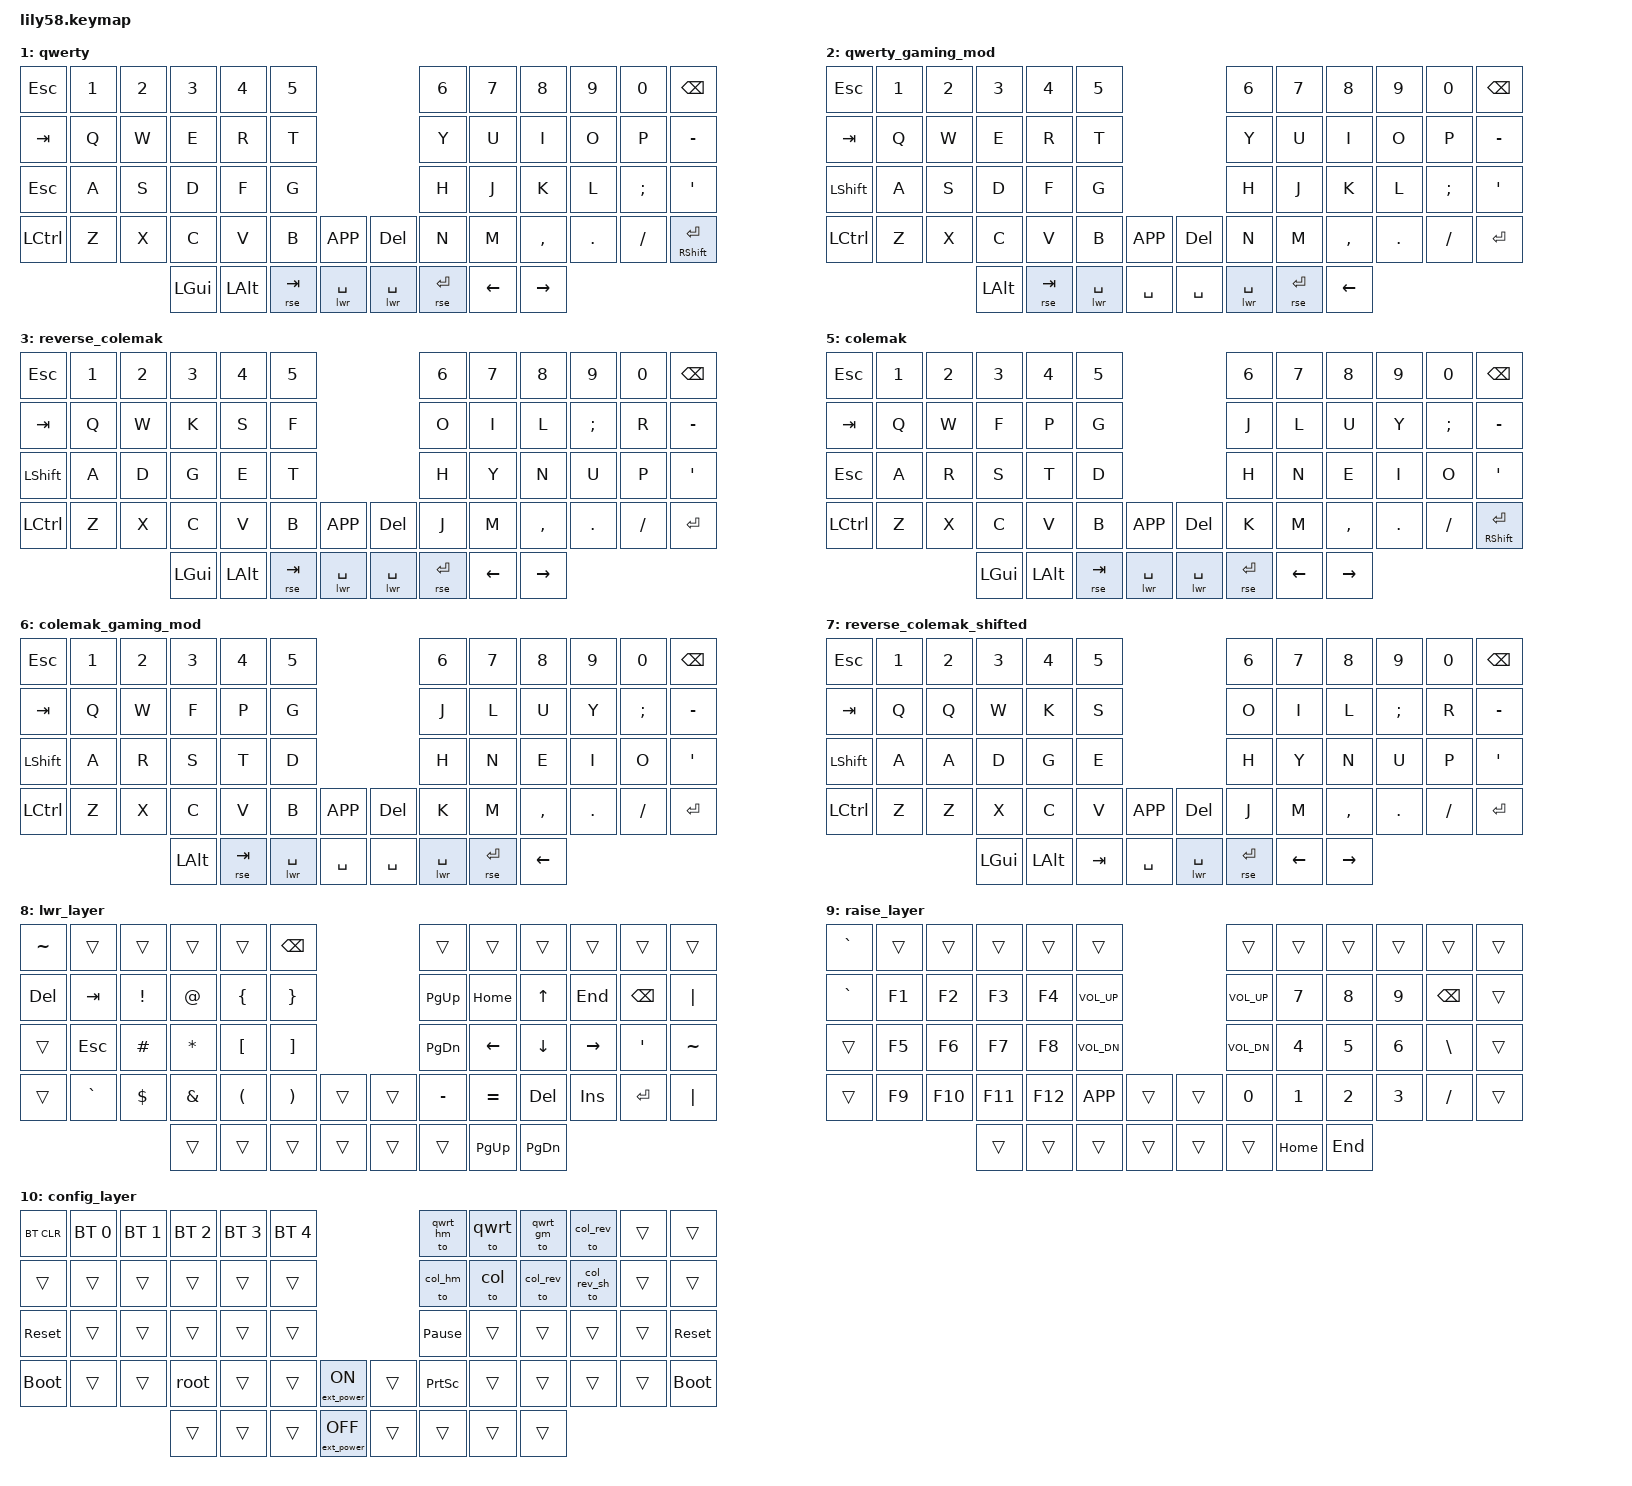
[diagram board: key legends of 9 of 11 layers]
/*
 * Copyright (c) 2020 The ZMK Contributors
 *
 * SPDX-License-Identifier: MIT
 */

#include <behaviors.dtsi>
#include <dt-bindings/zmk/bt.h>
#include <dt-bindings/zmk/keys.h>
#include <dt-bindings/zmk/ext_power.h>
#include <dt-bindings/zmk/outputs.h>

#define TAPPING_TERM 210
#define QUICK_TAP    150

#define ________ &trans

&lt {
	flavor = "hold-preferred";
	tapping-term-ms = <TAPPING_TERM>;
	quick-tap-ms = <QUICK_TAP>;
};

&mt {
	flavor = "balanced";
	tapping-term-ms = <TAPPING_TERM>;
	quick-tap-ms = <QUICK_TAP>;
};

/ {
	behaviors {
		gresc: grave_escape {
			label = "grave_escape";
			compatible = "zmk,behavior-mod-morph";
			#binding-cells = <0>;
			mods = <(MOD_LGUI|MOD_RGUI)>;
			bindings = <&kp ESC>, <&kp GRAVE>;
		};
		ht: hold_tap {
			label = "hold_tap";
			compatible = "zmk,behavior-hold-tap";
			#binding-cells = <2>;
			flavor = "balanced";
			tapping-term-ms = <TAPPING_TERM>;
			quick-tap-ms = <QUICK_TAP>;
			global-quick-tap;
			bindings = <&kp>, <&kp>;
		};
		lht: left_positional_hold_tap {
			label = "left_positional_hold_tap";
			compatible = "zmk,behavior-hold-tap";
			#binding-cells = <2>;
			flavor = "balanced";
			tapping-term-ms = <TAPPING_TERM>;
			quick-tap-ms = <QUICK_TAP>;
			bindings = <&kp>, <&kp>;
			hold-trigger-key-positions = <
			0	1	2	3	4	5				6	7	8	9	10	11
			12	13	14	15	16	17				18	19	20	21	22	23
			24	25	26	27	28	29				30	31	32	33	34	35
			36	37	38	39	40	41	42		43	44	45	46	47	48	49
						50	51	52	53		54	55	56	57	>;
		};
		rht: right_positional_hold_tap {
			label = "right_positional_hold_tap";
			compatible = "zmk,behavior-hold-tap";
			#binding-cells = <2>;
			flavor = "balanced";
			tapping-term-ms = <TAPPING_TERM>;
			quick-tap-ms = <QUICK_TAP>;
			bindings = <&kp>, <&kp>;
			hold-trigger-key-positions = <
			0	1	2	3	4	5				6	7	8	9	10	11
			12	13	14	15	16	17				18	19	20	21	22	23
			24	25	26	27	28	29				30	31	32	33	34	35
			36	37	38	39	40	41	42		43	44	45	46	47	48	49
						50	51	52	53		54	55	56	57	>;
		};
	};
};

/ {
	macros {
		root: root {
			label = "root";
            compatible = "zmk,behavior-macro";
            #binding-cells = <0>;
            wait-ms = <1>;
            tap-ms = <1>;
			bindings
			= <&macro_tap &kp O>
			, <&macro_tap &kp I>
			, <&macro_tap &kp U>
			, <&macro_tap &kp O>
			, <&macro_tap &kp I>
			, <&macro_tap &kp U>
			, <&macro_tap &kp O>
			, <&macro_tap &kp I>
			, <&macro_tap &kp U>
			, <&macro_tap &kp RET>
			;
		};
	};
};

#define qwrt_hm 0
#define qwrt 1
#define qwrt_gm 2
#define col_rev 3
#define col_hm 4
#define col 5
#define col_gm 6
#define col_rev_sh 7
#define lwr 8
#define rse 9
#define cfg 10

#define HRML(k1,k2,k3,k4) &lht LGUI k1   &lht LALT k2   &lht LSHFT k3   &lht LCTRL k4
#define HRMR(k1,k2,k3,k4) &rht RCTRL k1  &rht RSHFT k2  &rht RALT k3    &rht RGUI k4

#define COMBO(name, keypress, keypos) \
combo_##name {                        \
	timeout-ms = <50>;                \
	bindings = <keypress>;            \
	key-positions = <keypos>;         \
};
/* Combo key positions
0	1	2	3	4	5				6	7	8	9	10	11
12	13	14	15	16	17				18	19	20	21	22	23
24	25	26	27	28	29				30	31	32	33	34	35
36	37	38	39	40	41	42		43	44	45	46	47	48	49
			50	51	52	53		54	55	56	57				*/

/ {
	combos {
		compatible = "zmk,combos";
		COMBO(cfg,	&mo cfg,	52	55)
		COMBO(cfg_l,	&mo cfg,	50	51)
		COMBO(cfg_r,	&mo cfg,	56	57)
	};
};


/ {
	keymap {
		compatible = "zmk,keymap";

		qwerty_home_mod {
			bindings = <
&kp ESC		&kp N1	&kp N2	&kp N3		&kp N4		&kp N5										&kp N6		&kp N7		&kp N8		&kp N9	&kp N0	&kp BSPC
&kp TAB		&kp Q	&kp W	&kp E 		&kp R		&kp T										&kp Y		&kp U		&kp I		&kp O	&kp P	&kp MINUS
&kp ESC		HRML(A,		S,		D,			F)		&kp G										&kp H		HRMR(J,			K,			L,	SEMI)	&kp SQT
&kp LCTRL	&kp Z	&kp X	&kp C		&kp V		&kp B		&kp K_APP		&kp DEL			&kp N		&kp M		&kp COMMA &kp DOT &kp FSLH	&mt RSHFT ENTER
							&kp LGUI	&kp LALT	&lt rse TAB	&lt lwr SPACE	&lt lwr SPACE	&lt rse RET	&kp LEFT	&kp RIGHT
			>;

			sensor-bindings = <&inc_dec_kp C_VOL_UP C_VOL_DN>;
		};

		qwerty {
			bindings = <
&kp ESC		&kp N1	&kp N2	&kp N3		&kp N4		&kp N5										&kp N6			&kp N7		&kp N8		&kp N9	&kp N0		&kp BSPC
&kp TAB		&kp Q	&kp W 	&kp E		&kp R		&kp T										&kp Y			&kp U		&kp I		&kp O	&kp P		&kp MINUS
&kp ESC		&kp A	&kp S	&kp D		&kp F		&kp G										&kp H			&kp J		&kp K		&kp L	&kp SEMI	&kp SQT
&kp LCTRL	&kp Z	&kp X	&kp C		&kp V		&kp B		&kp K_APP		&kp DEL			&kp N			&kp M		&kp COMMA	&kp DOT	&kp FSLH	&mt RSHFT ENTER
							&kp LGUI	&kp LALT	&lt rse TAB	&lt lwr SPACE	&lt lwr SPACE	&lt rse RET		&kp LEFT	&kp RIGHT
			>;

			sensor-bindings = <&inc_dec_kp C_VOL_UP C_VOL_DN>;
		};

		qwerty_gaming_mod {
			bindings = <
&kp ESC		&kp N1	&kp N2	&kp N3		&kp N4		&kp N5										&kp N6			&kp N7		&kp N8		&kp N9	&kp N0		&kp BSPC
&kp TAB		&kp Q	&kp W 	&kp E		&kp R		&kp T										&kp Y			&kp U		&kp I		&kp O	&kp P		&kp MINUS
&kp LSHFT	&kp A	&kp S	&kp D		&kp F		&kp G										&kp H			&kp J		&kp K		&kp L	&kp SEMI	&kp SQT
&kp LCTRL	&kp Z	&kp X	&kp C		&kp V		&kp B			&kp K_APP	&kp DEL			&kp N			&kp M		&kp COMMA	&kp DOT	&kp FSLH	&kp ENTER
							&kp LALT	&lt rse TAB	&lt lwr SPACE	&kp SPACE	&kp SPACE		&lt lwr SPACE	&lt rse RET &kp LEFT
			>;

			sensor-bindings = <&inc_dec_kp C_VOL_UP C_VOL_DN>;
		};

		reverse_colemak {
    bindings = <
&kp ESC     &kp N1  &kp N2  &kp N3      &kp N4      &kp N5                                      &kp N6      &kp N7      &kp N8      &kp N9      &kp N0  &kp BSPC
&kp TAB     &kp Q   &kp W   &kp K   	&kp S 		&kp F									  	&kp O 		&kp I 		&kp L 		&kp SEMI 	&kp R  	&kp MINUS
&kp LSHFT	&kp A	&kp D 	&kp G 		&kp E 		&kp T									  	&kp H 		&kp Y 		&kp N 		&kp U 		&kp P 	&kp SQT
&kp LCTRL	&kp Z	&kp X	&kp C		&kp V		&kp B		&kp K_APP		&kp DEL			&kp J 		&kp M 		&kp COMMA	&kp DOT	&kp FSLH	&kp ENTER
                            &kp LGUI    &kp LALT    &lt rse TAB &lt lwr SPACE   &lt lwr SPACE  &lt rse RET &kp LEFT    &kp RIGHT
    >;
			sensor-bindings = <&inc_dec_kp C_VOL_UP C_VOL_DN>;
		};

		colemak_home_mod {
			bindings = <
&kp ESC		&kp N1	&kp N2	&kp N3		&kp N4		&kp N5										&kp N6		&kp N7		&kp N8		&kp N9	&kp N0	&kp BSPC
&kp TAB		&kp Q	&kp W	&kp F 		&kp P		&kp G										&kp J		&kp L		&kp U		&kp Y	&kp SEMI	&kp MINUS
&kp ESC		HRML(A,		R,		S,			T)		&kp D										&kp H		HRMR(N,			E,			I,	O)	&kp SQT
&kp LCTRL	&kp Z	&kp X	&kp C		&kp V		&kp B		&kp K_APP		&kp DEL			&kp K		&kp M		&kp COMMA &kp DOT &kp FSLH	&mt RSHFT ENTER
							&kp LGUI	&kp LALT	&lt rse TAB	&lt lwr SPACE	&lt lwr SPACE	&lt rse RET	&kp LEFT	&kp RIGHT
			>;

			sensor-bindings = <&inc_dec_kp C_VOL_UP C_VOL_DN>;
		};

		colemak {
			bindings = <
&kp ESC		&kp N1	&kp N2	&kp N3		&kp N4		&kp N5										&kp N6			&kp N7		&kp N8		&kp N9	&kp N0		&kp BSPC
&kp TAB		&kp Q	&kp W 	&kp F		&kp P		&kp G										&kp J			&kp L		&kp U		&kp Y	&kp SEMI	&kp MINUS
&kp ESC		&kp A	&kp R	&kp S		&kp T		&kp D										&kp H			&kp N		&kp E		&kp I	&kp O		&kp SQT
&kp LCTRL	&kp Z	&kp X	&kp C		&kp V		&kp B		&kp K_APP		&kp DEL			&kp K			&kp M		&kp COMMA	&kp DOT	&kp FSLH	&mt RSHFT ENTER
							&kp LGUI	&kp LALT	&lt rse TAB	&lt lwr SPACE	&lt lwr SPACE	&lt rse RET		&kp LEFT	&kp RIGHT
			>;

			sensor-bindings = <&inc_dec_kp C_VOL_UP C_VOL_DN>;
		};

		colemak_gaming_mod {
			bindings = <
&kp ESC		&kp N1	&kp N2	&kp N3		&kp N4		&kp N5										&kp N6			&kp N7		&kp N8		&kp N9	&kp N0		&kp BSPC
&kp TAB		&kp Q	&kp W 	&kp F		&kp P		&kp G										&kp J			&kp L		&kp U		&kp Y	&kp SEMI	&kp MINUS
&kp LSHFT	&kp A	&kp R	&kp S		&kp T		&kp D										&kp H			&kp N		&kp E		&kp I	&kp O		&kp SQT
&kp LCTRL	&kp Z	&kp X	&kp C		&kp V		&kp B			&kp K_APP	&kp DEL			&kp K			&kp M		&kp COMMA	&kp DOT	&kp FSLH	&kp ENTER
							&kp LALT	&lt rse TAB	&lt lwr SPACE	&kp SPACE	&kp SPACE		&lt lwr SPACE	&lt rse RET &kp LEFT
			>;

			sensor-bindings = <&inc_dec_kp C_VOL_UP C_VOL_DN>;
		};

		reverse_colemak_shifted {
			bindings = <
&kp ESC		&kp N1	&kp N2	&kp N3		&kp N4		&kp N5										&kp N6		&kp N7		&kp N8		&kp N9		&kp N0	&kp BSPC
&kp TAB		&kp Q	&kp Q	&kp W 		&kp K		&kp S										&kp O		&kp I		&kp L		&kp SEMI	&kp R	&kp MINUS
&kp LSHFT	&kp A	&kp A	&kp D		&kp G		&kp E										&kp H		&kp Y		&kp N		&kp U		&kp P	&kp SQT
&kp LCTRL	&kp Z	&kp Z	&kp X		&kp C		&kp V		&kp K_APP		&kp DEL			&kp J		&kp M		&kp COMMA &kp DOT &kp FSLH	&kp ENTER
							&kp LGUI	&kp LALT	&kp TAB		&kp SPACE	&lt lwr SPACE	&lt rse RET	&kp LEFT	&kp RIGHT
			>;

			sensor-bindings = <&inc_dec_kp C_VOL_UP C_VOL_DN>;
		};

		lwr_layer {
			bindings = <
&kp TILDE	&trans		&trans		&trans		&trans		&kp BSPC					&trans			&trans		&trans		&trans		&trans		&trans
&kp DEL		&kp TAB		&kp EXCL	&kp AT		&kp LBRC	&kp RBRC					&kp PG_UP		&kp HOME	&kp UP		&kp END		&kp BSPC	&kp PIPE
&trans		&kp ESC		&kp HASH	&kp ASTRK	&kp LBKT	&kp RBKT					&kp PG_DN		&kp LEFT	&kp DOWN	&kp RIGHT	&kp SQT		&kp TILDE
&trans		&kp GRAVE	&kp DLLR	&kp AMPS	&kp LPAR	&kp RPAR	&trans	&trans	&kp MINUS		&kp EQUAL	&kp DEL		&kp INS		&kp RET		&kp PIPE
						&trans		&trans		&trans		&trans		&trans	&trans	&kp PG_UP		&kp PG_DN
			>;

			sensor-bindings = <&inc_dec_kp C_VOL_UP C_VOL_DN>;
		};

		raise_layer {
			bindings = <
&kp GRAVE	&trans		&trans		&trans		&trans		&trans						&trans			&trans		&trans		&trans		&trans		&trans
&kp GRAVE	&kp F1		&kp F2		&kp F3		&kp F4		&kp C_VOL_UP				&kp C_VOL_UP	&kp N7		&kp N8		&kp N9		&kp BSPC	&trans
&trans		&kp F5		&kp F6		&kp F7		&kp F8		&kp C_VOL_DN				&kp C_VOL_DN	&kp N4		&kp N5		&kp N6		&kp BSLH	&trans
&trans		&kp F9		&kp F10		&kp F11		&kp F12		&kp K_APP	&trans	&trans	&kp N0			&kp N1		&kp N2		&kp N3		&kp FSLH	&trans
									&trans		&trans		&trans		&trans	&trans	&trans			&kp HOME	&kp END
			>;

			sensor-bindings = <&inc_dec_kp C_VOL_UP C_VOL_DN>;
		};

		config_layer {
			bindings = <
&bt BT_CLR	&bt BT_SEL 0	&bt BT_SEL 1	&bt BT_SEL 2	&bt BT_SEL 3	&bt BT_SEL 4							&to qwrt_hm		&to qwrt	&to qwrt_gm	&to col_rev	&trans		&trans
&trans		&trans			&trans			&trans			&trans			&trans							 		&to col_hm		&to col		&to col_rev	&to col_rev_sh &trans		&trans
&sys_reset	&trans			&trans			&trans			&trans			&trans							 		&kp PAUSE_BREAK	&trans		&trans		&trans		&trans		&sys_reset
&bootloader	&trans			&trans			&root			&trans			&trans		&ext_power EP_ON	&trans 	&kp PSCRN		&trans		&trans		&trans		&trans		&bootloader
											&trans			&trans			&trans		&ext_power EP_OFF	&trans 	&trans			&trans		&trans
			>;

			sensor-bindings = <&inc_dec_kp C_VOL_UP C_VOL_DN>;
		};
	};
};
